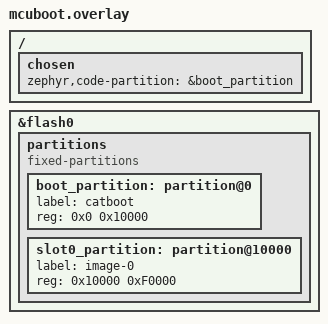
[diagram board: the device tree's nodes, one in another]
&flash0 {
	/delete-node/ partitions;
	partitions {
		compatible = "fixed-partitions";
		#address-cells = < 0x1 >;
		#size-cells = < 0x1 >;
		boot_partition: partition@0 {
			label = "catboot";
			reg = < 0x0 0x10000 >;
		};
		slot0_partition: partition@10000 {
			label = "image-0";
			reg = < 0x10000 0xF0000 >;
		};
	};
};

/ {
	chosen {
		zephyr,code-partition = &boot_partition;
	};
};
